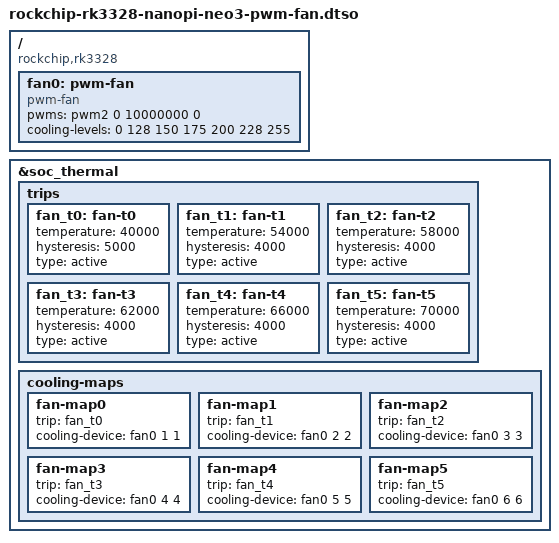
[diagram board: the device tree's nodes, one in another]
/dts-v1/;
/plugin/;

/*
 * NanoPi NEO3 onboard fan connector (CON4, 2-pin JST ZH 1.5mm, 5V).
 * CON4 is switched from VDD_5V by an AO3415A P-FET driven via a 2N7002
 * from RK3328 PWM2 / GPIO2_A6 (schematic sheet 11, "FAN"), so PWM duty
 * controls fan speed. The PWM must be slow (100 Hz): the P-FET gate
 * recharges through 100k pull-ups (~70us), so at high PWM frequencies
 * the FET never switches off and any duty behaves like full speed.
 * Registers a pwm-fan cooling device on the SoC thermal zone with a
 * continuous 50% baseline above 40C (off below 35C), stepping through
 * 59/69/78/89/100% at 54/58/62/66/70C. The always-on baseline keeps
 * the SoC temperature steady instead of on/off cycling around the
 * lowest trip point.
 */

/ {
	compatible = "rockchip,rk3328";

	fragment@0 {
		target-path = "/";
		__overlay__ {
			fan0: pwm-fan {
				compatible = "pwm-fan";
				pwms = <&pwm2 0 10000000 0>;
				cooling-levels = <0 128 150 175 200 228 255>;
				#cooling-cells = <2>;
			};
		};
	};

	fragment@1 {
		target = <&soc_thermal>;
		__overlay__ {
			trips {
				fan_t0: fan-t0 { temperature = <40000>; hysteresis = <5000>; type = "active"; };
				fan_t1: fan-t1 { temperature = <54000>; hysteresis = <4000>; type = "active"; };
				fan_t2: fan-t2 { temperature = <58000>; hysteresis = <4000>; type = "active"; };
				fan_t3: fan-t3 { temperature = <62000>; hysteresis = <4000>; type = "active"; };
				fan_t4: fan-t4 { temperature = <66000>; hysteresis = <4000>; type = "active"; };
				fan_t5: fan-t5 { temperature = <70000>; hysteresis = <4000>; type = "active"; };
			};
			cooling-maps {
				fan-map0 { trip = <&fan_t0>; cooling-device = <&fan0 1 1>; };
				fan-map1 { trip = <&fan_t1>; cooling-device = <&fan0 2 2>; };
				fan-map2 { trip = <&fan_t2>; cooling-device = <&fan0 3 3>; };
				fan-map3 { trip = <&fan_t3>; cooling-device = <&fan0 4 4>; };
				fan-map4 { trip = <&fan_t4>; cooling-device = <&fan0 5 5>; };
				fan-map5 { trip = <&fan_t5>; cooling-device = <&fan0 6 6>; };
			};
		};
	};
};
